AUTOSAR XML (schema 00046)
package /ComponentTypes
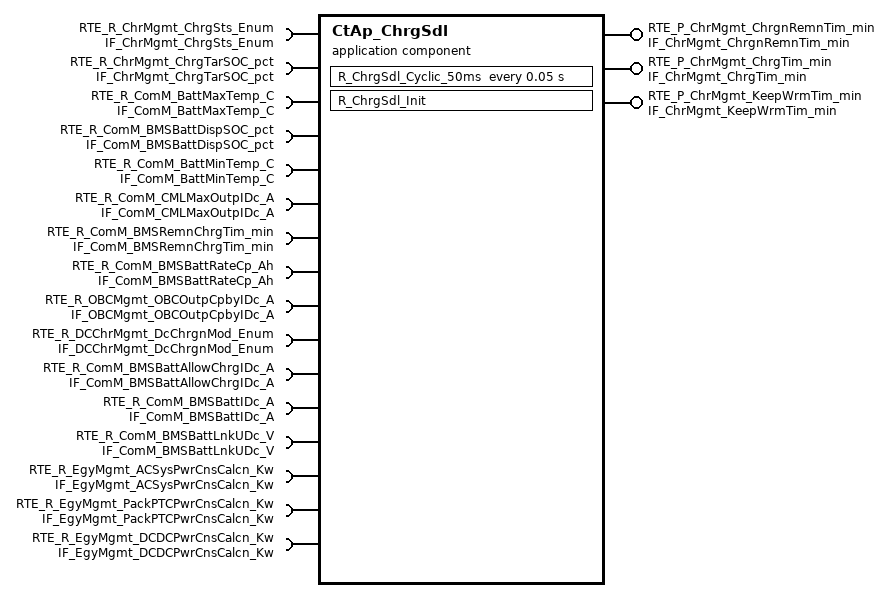
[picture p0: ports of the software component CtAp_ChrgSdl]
  application sw component type CtAp_ChrgSdl
    provide port RTE_P_ChrMgmt_ChrgnRemnTim_min: nonqueued-sender-com-spec{data-element=tec_ChrgMgmt_ChrgnRemnTim_min, init-value=0}, provided-interface=IF_ChrMgmt_ChrgnRemnTim_min
    provide port RTE_P_ChrMgmt_ChrgTim_min: nonqueued-sender-com-spec{data-element=tec_ChrMgmt_ChrgTim_min, init-value=0}, provided-interface=IF_ChrMgmt_ChrgTim_min
    provide port RTE_P_ChrMgmt_KeepWrmTim_min: nonqueued-sender-com-spec{data-element=tec_ChrMgmt_KeepWrmTim_min, init-value=0}, provided-interface=IF_ChrMgmt_KeepWrmTim_min
    16 x require port:
      RTE_R_ChrMgmt_ChrgSts_Enum: nonqueued-receiver-com-spec{data-element=tec_ChrMgmt_ChrgSts_Enum, filter=data-filter-type=ALWAYS, init-value=0}, required-interface=IF_ChrMgmt_ChrgSts_Enum
      RTE_R_ChrMgmt_ChrgTarSOC_pct: nonqueued-receiver-com-spec{data-element=tec_ChrMgmt_ChrgTarSOC_pct, filter=data-filter-type=ALWAYS, init-value=0}, required-interface=IF_ChrMgmt_ChrgTarSOC_pct
      RTE_R_ComM_BattMaxTemp_C: nonqueued-receiver-com-spec{data-element=tec_ComM_BMSBattMaxTemp_C, filter=data-filter-type=ALWAYS, init-value=0}, required-interface=IF_ComM_BattMaxTemp_C
      RTE_R_ComM_BMSBattDispSOC_pct: nonqueued-receiver-com-spec{data-element=tec_ComM_BMSBattDispSOC_pct, filter=data-filter-type=ALWAYS, init-value=0}, required-interface=IF_ComM_BMSBattDispSOC_pct
      RTE_R_ComM_BattMinTemp_C: nonqueued-receiver-com-spec{data-element=tec_ComM_BMSBattMinTemp_C, filter=data-filter-type=ALWAYS, init-value=0}, required-interface=IF_ComM_BattMinTemp_C
      RTE_R_ComM_CMLMaxOutpIDc_A: nonqueued-receiver-com-spec{data-element=tec_ComM_CMLMaxOutpIDc_A, filter=data-filter-type=ALWAYS, init-value=0}, required-interface=IF_ComM_CMLMaxOutpIDc_A
      RTE_R_ComM_BMSRemnChrgTim_min: nonqueued-receiver-com-spec{data-element=tec_ComM_BMSRemnChrgTim_min, filter=data-filter-type=ALWAYS, init-value=0}, required-interface=IF_ComM_BMSRemnChrgTim_min
      RTE_R_ComM_BMSBattRateCp_Ah: nonqueued-receiver-com-spec{data-element=tec_ComM_BMSBattRateCp_Ah, filter=data-filter-type=ALWAYS, init-value=0}, required-interface=IF_ComM_BMSBattRateCp_Ah
      RTE_R_OBCMgmt_OBCOutpCpbyIDc_A: nonqueued-receiver-com-spec{data-element=tec_OBCMgmt_OBCOutpCpbyIDc_A, filter=data-filter-type=ALWAYS, init-value=0}, required-interface=IF_OBCMgmt_OBCOutpCpbyIDc_A
      RTE_R_DCChrMgmt_DcChrgnMod_Enum: nonqueued-receiver-com-spec{data-element=tec_DCChrMgmt_DcChrgnMod_Enum, filter=data-filter-type=ALWAYS, init-value=0}, required-interface=IF_DCChrMgmt_DcChrgnMod_Enum
      RTE_R_ComM_BMSBattAllowChrgIDc_A: nonqueued-receiver-com-spec{data-element=tec_ComM_BMSBattAllowChrgIDc_A, filter=data-filter-type=ALWAYS, init-value=0}, required-interface=IF_ComM_BMSBattAllowChrgIDc_A
      RTE_R_ComM_BMSBattIDc_A: nonqueued-receiver-com-spec{data-element=tec_ComM_BMSBattIDc_A, filter=data-filter-type=ALWAYS, init-value=0}, required-interface=IF_ComM_BMSBattIDc_A
      RTE_R_ComM_BMSBattLnkUDc_V: nonqueued-receiver-com-spec{data-element=tec_ComM_BMSBattLnkUDc_V, filter=data-filter-type=ALWAYS, init-value=0}, required-interface=IF_ComM_BMSBattLnkUDc_V
      RTE_R_EgyMgmt_ACSysPwrCnsCalcn_Kw: nonqueued-receiver-com-spec{data-element=tec_EgyMgmt_ACSysPwrCnsCalcn_Kw, filter=data-filter-type=ALWAYS, init-value=0}, required-interface=IF_EgyMgmt_ACSysPwrCnsCalcn_Kw
      RTE_R_EgyMgmt_PackPTCPwrCnsCalcn_Kw: nonqueued-receiver-com-spec{data-element=tec_EgyMgmt_PackPTCPwrCnsCalcn_Kw, filter=data-filter-type=ALWAYS, init-value=0}, required-interface=IF_EgyMgmt_PackPTCPwrCnsCalcn_Kw
      RTE_R_EgyMgmt_DCDCPwrCnsCalcn_Kw: nonqueued-receiver-com-spec{data-element=tec_EgyMgmt_DCDCPwrCnsCalcn_Kw, filter=data-filter-type=ALWAYS, init-value=0}, required-interface=IF_EgyMgmt_DCDCPwrCnsCalcn_Kw
    behavior CtAp_ChrgSdl_InternalBehavior
      timing event TMT_R_ChrgSdl_Cyclic_50ms: start-on-event=R_ChrgSdl_Cyclic_50ms, period=0.05
      init event CtAp_ChrgSdl_InitEvent: start-on-event=R_ChrgSdl_Init
      runnable R_ChrgSdl_Cyclic_50ms
        data-receive-point-by-arguments:
          16 x access:
            REC_RTE_R_ChrMgmt_ChrgSts_Enum_tec_ChrMgmt_ChrgSts_Enum: accessed-variable=RTE_R_ChrMgmt_ChrgSts_Enum.tec_ChrMgmt_ChrgSts_Enum
            REC_RTE_R_ChrMgmt_ChrgTarSOC_pct_tec_ChrMgmt_ChrgTarSOC_pct: accessed-variable=RTE_R_ChrMgmt_ChrgTarSOC_pct.tec_ChrMgmt_ChrgTarSOC_pct
            REC_RTE_R_ComM_BMSBattDispSOC_pct_tec_ComM_BMSBattDispSOC_pct: accessed-variable=RTE_R_ComM_BMSBattDispSOC_pct.tec_ComM_BMSBattDispSOC_pct
            REC_RTE_R_ComM_BMSBattRateCp_Ah_tec_ComM_BMSBattRateCp_Ah: accessed-variable=RTE_R_ComM_BMSBattRateCp_Ah.tec_ComM_BMSBattRateCp_Ah
            REC_RTE_R_ComM_BMSRemnChrgTim_min_tec_ComM_BMSRemnChrgTim_min: accessed-variable=RTE_R_ComM_BMSRemnChrgTim_min.tec_ComM_BMSRemnChrgTim_min
            REC_RTE_R_ComM_BattMaxTemp_C_tec_ComM_BMSBattMaxTemp_C: accessed-variable=RTE_R_ComM_BattMaxTemp_C.tec_ComM_BMSBattMaxTemp_C
            REC_RTE_R_ComM_BattMinTemp_C_tec_ComM_BMSBattMinTemp_C: accessed-variable=RTE_R_ComM_BattMinTemp_C.tec_ComM_BMSBattMinTemp_C
            REC_RTE_R_ComM_CMLMaxOutpIDc_A_tec_ComM_CMLMaxOutpIDc_A: accessed-variable=RTE_R_ComM_CMLMaxOutpIDc_A.tec_ComM_CMLMaxOutpIDc_A
            REC_RTE_R_DCChrMgmt_DcChrgnMod_Enum_tec_DCChrMgmt_DcChrgnMod_Enum: accessed-variable=RTE_R_DCChrMgmt_DcChrgnMod_Enum.tec_DCChrMgmt_DcChrgnMod_Enum
            REC_RTE_R_OBCMgmt_OBCOutpCpbyIDc_A_tec_OBCMgmt_OBCOutpCpbyIDc_A: accessed-variable=RTE_R_OBCMgmt_OBCOutpCpbyIDc_A.tec_OBCMgmt_OBCOutpCpbyIDc_A
            REC_RTE_R_ComM_BMSBattAllowChrgIDc_A_tec_ComM_BMSBattAllowChrgIDc_A: accessed-variable=RTE_R_ComM_BMSBattAllowChrgIDc_A.tec_ComM_BMSBattAllowChrgIDc_A
            REC_RTE_R_ComM_BMSBattIDc_A_tec_ComM_BMSBattIDc_A: accessed-variable=RTE_R_ComM_BMSBattIDc_A.tec_ComM_BMSBattIDc_A
            REC_RTE_R_ComM_BMSBattLnkUDc_V_tec_ComM_BMSBattLnkUDc_V: accessed-variable=RTE_R_ComM_BMSBattLnkUDc_V.tec_ComM_BMSBattLnkUDc_V
            REC_RTE_R_EgyMgmt_ACSysPwrCnsCalcn_Kw_tec_EgyMgmt_ACSysPwrCnsCalcn_Kw: accessed-variable=RTE_R_EgyMgmt_ACSysPwrCnsCalcn_Kw.tec_EgyMgmt_ACSysPwrCnsCalcn_Kw
            REC_RTE_R_EgyMgmt_DCDCPwrCnsCalcn_Kw_tec_EgyMgmt_DCDCPwrCnsCalcn_Kw: accessed-variable=RTE_R_EgyMgmt_DCDCPwrCnsCalcn_Kw.tec_EgyMgmt_DCDCPwrCnsCalcn_Kw
            REC_RTE_R_EgyMgmt_PackPTCPwrCnsCalcn_Kw_tec_EgyMgmt_PackPTCPwrCnsCalcn_Kw: accessed-variable=RTE_R_EgyMgmt_PackPTCPwrCnsCalcn_Kw.tec_EgyMgmt_PackPTCPwrCnsCalcn_Kw
        data-send-points:
          access SEND_RTE_P_ChrMgmt_ChrgTim_min_tec_ChrMgmt_ChrgTim_min: accessed-variable=RTE_P_ChrMgmt_ChrgTim_min.tec_ChrMgmt_ChrgTim_min
          access SEND_RTE_P_ChrMgmt_ChrgnRemnTim_min_tec_ChrgMgmt_ChrgnRemnTim_min: accessed-variable=RTE_P_ChrMgmt_ChrgnRemnTim_min.tec_ChrgMgmt_ChrgnRemnTim_min
          access SEND_RTE_P_ChrMgmt_KeepWrmTim_min_tec_ChrMgmt_KeepWrmTim_min: accessed-variable=RTE_P_ChrMgmt_KeepWrmTim_min.tec_ChrMgmt_KeepWrmTim_min
      runnable R_ChrgSdl_Init
  swc implementation CtAp_ChrgSdl_Implementation: behavior=CtAp_ChrgSdl_InternalBehavior
